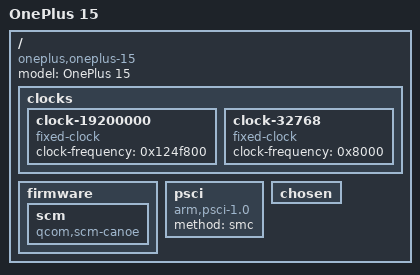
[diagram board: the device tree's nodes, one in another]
/dts-v1/;

/ {
	#address-cells = <0x02>;
	#size-cells = <0x02>;
	model = "OnePlus 15";
	compatible = "oneplus,oneplus-15", "qcom,canoe";

	clocks {

		clock-19200000 {
			compatible = "fixed-clock";
			#clock-cells = <0x00>;
			clock-frequency = <0x124f800>;
		};

		clock-32768 {
			compatible = "fixed-clock";
			#clock-cells = <0x00>;
			clock-frequency = <0x8000>;
		};
	};

	firmware {

		scm {
			compatible = "qcom,scm-canoe", "qcom,scm";
		};
	};

	psci {
		compatible = "arm,psci-1.0";
		method = "smc";
	};

	chosen {
	};
};
